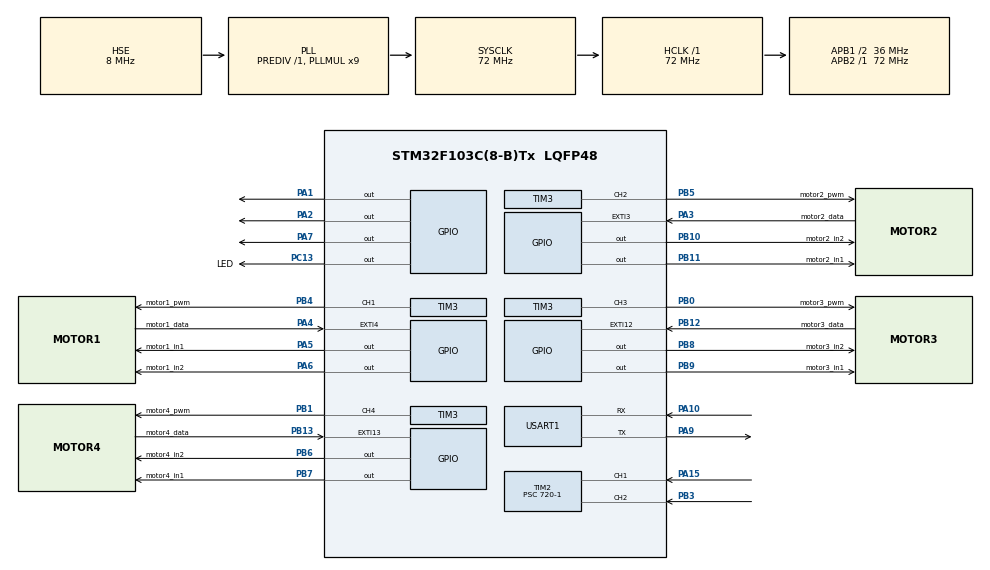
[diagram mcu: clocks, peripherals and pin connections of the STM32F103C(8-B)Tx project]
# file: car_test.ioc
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Mcu.Family=STM32F1
Mcu.Name=STM32F103C(8-B)Tx
Mcu.Package=LQFP48
NVIC.EXTI15_10_IRQn=true\:1\:0\:true\:false\:true\:true\:true
NVIC.EXTI3_IRQn=true\:1\:0\:true\:false\:true\:true\:true
NVIC.EXTI4_IRQn=true\:1\:0\:true\:false\:true\:true\:true
NVIC.PriorityGroup=NVIC_PRIORITYGROUP_4
NVIC.TIM1_UP_IRQn=true\:0\:0\:false\:false\:true\:true\:true
NVIC.TIM2_IRQn=true\:2\:0\:true\:false\:true\:true\:true
PA1.PinState=GPIO_PIN_RESET
PA1.Signal=GPIO_Output
PA10.Mode=Asynchronous
PA10.Signal=USART1_RX
PA13.Mode=Serial_Wire
PA13.Signal=SYS_JTMS-SWDIO
PA14.Mode=Serial_Wire
PA14.Signal=SYS_JTCK-SWCLK
PA15.Signal=S_TIM2_CH1_ETR
PA2.Signal=GPIO_Output
PA3.GPIO_Label=motor2_data
PA3.Signal=GPXTI3
PA4.GPIO_Label=motor1_data
PA4.GPIO_ModeDefaultEXTI=GPIO_MODE_IT_FALLING
PA4.GPIO_PuPd=GPIO_PULLUP
PA4.Signal=GPXTI4
PA5.GPIO_Label=motor1_in1
PA5.Signal=GPIO_Output
PA6.GPIO_Label=motor1_in2
PA6.Signal=GPIO_Output
PA7.Signal=GPIO_Output
PA9.Mode=Asynchronous
PA9.Signal=USART1_TX
PB0.GPIO_Label=motor3_pwm
PB0.Signal=S_TIM3_CH3
PB1.GPIO_Label=motor4_pwm
PB1.Signal=S_TIM3_CH4
PB10.GPIO_Label=motor2_in2
PB10.Signal=GPIO_Output
PB11.GPIO_Label=motor2_in1
PB11.Signal=GPIO_Output
PB12.GPIO_Label=motor3_data
PB12.Signal=GPXTI12
PB13.GPIO_Label=motor4_data
PB13.Signal=GPXTI13
PB3.Signal=S_TIM2_CH2
PB4.GPIO_Label=motor1_pwm
PB4.Signal=S_TIM3_CH1
PB5.GPIO_Label=motor2_pwm
PB5.Signal=S_TIM3_CH2
PB6.GPIO_Label=motor4_in2
PB6.Signal=GPIO_Output
PB7.GPIO_Label=motor4_in1
PB7.Signal=GPIO_Output
PB8.GPIO_Label=motor3_in2
PB8.Signal=GPIO_Output
PB9.GPIO_Label=motor3_in1
PB9.Signal=GPIO_Output
PC13-TAMPER-RTC.GPIO_Label=LED
PC13-TAMPER-RTC.Signal=GPIO_Output
PD0-OSC_IN.Mode=HSE-External-Oscillator
PD0-OSC_IN.Signal=RCC_OSC_IN
PD1-OSC_OUT.Mode=HSE-External-Oscillator
PD1-OSC_OUT.Signal=RCC_OSC_OUT
ProjectManager.HeapSize=0x200
ProjectManager.StackSize=0x400
ProjectManager.TargetToolchain=MDK-ARM V5.27
RCC.AHBFreq_Value=72000000
RCC.APB1CLKDivider=RCC_HCLK_DIV2
RCC.APB1Freq_Value=36000000
RCC.APB1TimFreq_Value=72000000
RCC.APB2Freq_Value=72000000
RCC.APB2TimFreq_Value=72000000
RCC.HCLKFreq_Value=72000000
RCC.PLLMUL=RCC_PLL_MUL9
RCC.PLLSourceVirtual=RCC_PLLSOURCE_HSE
RCC.SYSCLKFreq_VALUE=72000000
RCC.SYSCLKSource=RCC_SYSCLKSOURCE_PLLCLK
RCC.USBFreq_Value=72000000
SH.S_TIM2_CH1_ETR.0=TIM2_CH1,Input_Capture1_from_TI1
SH.S_TIM2_CH2.0=TIM2_CH2,Input_Capture2_from_TI2
SH.S_TIM3_CH1.0=TIM3_CH1,PWM Generation1 CH1
SH.S_TIM3_CH2.0=TIM3_CH2,PWM Generation2 CH2
SH.S_TIM3_CH3.0=TIM3_CH3,PWM Generation3 CH3
SH.S_TIM3_CH4.0=TIM3_CH4,PWM Generation4 CH4
TIM1.Period=10000-1
TIM1.Prescaler=7200-1
TIM2.Channel-Input_Capture1_from_TI1=TIM_CHANNEL_1
TIM2.Channel-Input_Capture2_from_TI2=TIM_CHANNEL_2
TIM2.Period=0xFFFF
TIM2.Prescaler=720-1
TIM3.AutoReloadPreload=TIM_AUTORELOAD_PRELOAD_ENABLE
TIM3.Channel-PWM\ Generation1\ CH1=TIM_CHANNEL_1
TIM3.Channel-PWM\ Generation2\ CH2=TIM_CHANNEL_2
TIM3.Channel-PWM\ Generation3\ CH3=TIM_CHANNEL_3
TIM3.Channel-PWM\ Generation4\ CH4=TIM_CHANNEL_4
TIM3.Period=1000
TIM3.Pulse-PWM\ Generation1\ CH1=1000
TIM3.Pulse-PWM\ Generation2\ CH2=1000
TIM3.Pulse-PWM\ Generation3\ CH3=1000
TIM3.Pulse-PWM\ Generation4\ CH4=1000
USART1.VirtualMode=VM_ASYNC
VP_TIM1_VS_ClockSourceINT.Mode=Internal
VP_TIM2_VS_ClockSourceINT.Mode=Internal
VP_TIM3_VS_ClockSourceINT.Mode=Internal
board=custom

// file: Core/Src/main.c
/* USER CODE BEGIN Header */
/*
函数名：
作用：
备注：
*/
/* USER CODE END Header */
#include "main.h"
#include "tim.h"
#include "usart.h"
#include "gpio.h"

/* USER CODE BEGIN Includes */
#include "wcnm.h"
/* USER CODE END Includes */

void SystemClock_Config(void);

int main(void)
{

  /* MCU Configuration--------------------------------------------------------*/

  /* Reset of all peripherals, Initializes the Flash interface and the Systick. */
  HAL_Init();

  /* USER CODE BEGIN Init */
	motor_drive_init();
  /* USER CODE END Init */

  /* Configure the system clock */
  SystemClock_Config();

  /* Initialize all configured peripherals */
  MX_GPIO_Init();
  MX_USART1_UART_Init();
  MX_TIM2_Init();
  MX_TIM1_Init();
  MX_TIM3_Init();
  /* USER CODE BEGIN 2 */
	HAL_TIM_IC_Start_IT(&htim2,TIM_CHANNEL_1);//开启中断
	HAL_TIM_IC_Start_IT(&htim2,TIM_CHANNEL_2);
	HAL_TIM_Base_Start_IT(&htim1); //开启定时器
	HAL_TIM_PWM_Start(&htim3,TIM_CHANNEL_1);//电机1234pwm控制初始化
	HAL_TIM_PWM_Start(&htim3,TIM_CHANNEL_2);
	HAL_TIM_PWM_Start(&htim3,TIM_CHANNEL_3);//电机1234pwm控制初始化
	HAL_TIM_PWM_Start(&htim3,TIM_CHANNEL_4);
  /* USER CODE END 2 */

  /* Infinite loop */
  while (1)
  {

  }
}

void SystemClock_Config(void)
{
  RCC_OscInitTypeDef RCC_OscInitStruct = {0};
  RCC_ClkInitTypeDef RCC_ClkInitStruct = {0};

  /** Initializes the RCC Oscillators according to the specified parameters
  * in the RCC_OscInitTypeDef structure.
  */
  RCC_OscInitStruct.OscillatorType = RCC_OSCILLATORTYPE_HSE;
  RCC_OscInitStruct.HSEState = RCC_HSE_ON;
  RCC_OscInitStruct.HSEPredivValue = RCC_HSE_PREDIV_DIV1;
  RCC_OscInitStruct.HSIState = RCC_HSI_ON;
  RCC_OscInitStruct.PLL.PLLState = RCC_PLL_ON;
  RCC_OscInitStruct.PLL.PLLSource = RCC_PLLSOURCE_HSE;
  RCC_OscInitStruct.PLL.PLLMUL = RCC_PLL_MUL9;
  if (HAL_RCC_OscConfig(&RCC_OscInitStruct) != HAL_OK)
  {
    Error_Handler();
  }
  /** Initializes the CPU, AHB and APB buses clocks
  */
  RCC_ClkInitStruct.ClockType = RCC_CLOCKTYPE_HCLK|RCC_CLOCKTYPE_SYSCLK
                              |RCC_CLOCKTYPE_PCLK1|RCC_CLOCKTYPE_PCLK2;
  RCC_ClkInitStruct.SYSCLKSource = RCC_SYSCLKSOURCE_PLLCLK;
  RCC_ClkInitStruct.AHBCLKDivider = RCC_SYSCLK_DIV1;
  RCC_ClkInitStruct.APB1CLKDivider = RCC_HCLK_DIV2;
  RCC_ClkInitStruct.APB2CLKDivider = RCC_HCLK_DIV1;

  if (HAL_RCC_ClockConfig(&RCC_ClkInitStruct, FLASH_LATENCY_2) != HAL_OK)
  {
    Error_Handler();
  }
}

void Error_Handler(void)
{
  __disable_irq();
  while (1)
  {
  }
}

/************************ (C) COPYRIGHT STMicroelectronics *****END OF FILE****/
